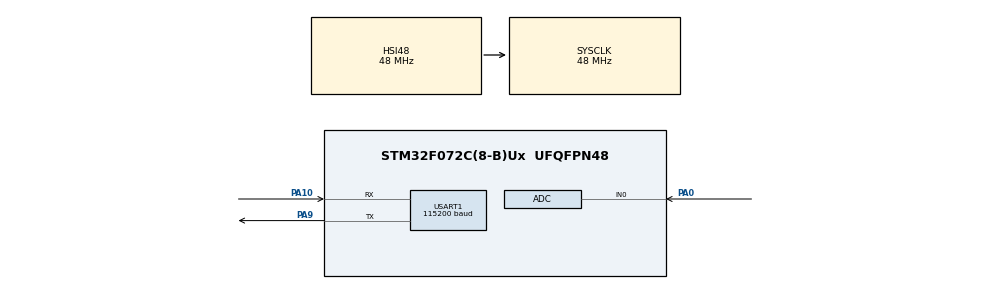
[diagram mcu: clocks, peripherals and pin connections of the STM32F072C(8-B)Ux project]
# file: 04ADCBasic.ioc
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Mcu.Family=STM32F0
Mcu.Name=STM32F072C(8-B)Ux
Mcu.Package=UFQFPN48
PA0.Mode=IN0
PA0.Signal=ADC_IN0
PA10.Mode=Asynchronous
PA10.Signal=USART1_RX
PA13.Mode=Serial_Wire
PA13.Signal=SYS_SWDIO
PA14.Mode=Serial_Wire
PA14.Signal=SYS_SWCLK
PA9.Mode=Asynchronous
PA9.Signal=USART1_TX
ProjectManager.HeapSize=0x200
ProjectManager.StackSize=0x400
ProjectManager.TargetToolchain=MDK-ARM V5.32
RCC.SYSCLKFreq_VALUE=48000000
RCC.SYSCLKSource=RCC_SYSCLKSOURCE_HSI48
USART1.BaudRate=115200
USART1.VirtualMode-Asynchronous=VM_ASYNC
board=custom

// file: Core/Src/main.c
/* USER CODE BEGIN Header */
/**
  ******************************************************************************
  * @file           : main.c
  * @brief          : Main program body
  ******************************************************************************
  * @attention
  *
  * Copyright (c) 2026 STMicroelectronics.
  * All rights reserved.
  *
  * This software is licensed under terms that can be found in the LICENSE file
  * in the root directory of this software component.
  * If no LICENSE file comes with this software, it is provided AS-IS.
  *
  ******************************************************************************
  */
/* USER CODE END Header */
#include "main.h"

/* USER CODE BEGIN Includes */
#include <stdio.h>
/*
 * ADC_IN0 单次采样：PA0 模拟输入，12 位结果范围 0..4095；
 * USART1 PA9 输出原始值和估算电压。PA0 必须保持在 0..VDDA，
 * 高阻信号源可能需要更长采样时间或外部缓冲器。
 */
/* USER CODE END Includes */

/* USER CODE BEGIN PD */
/* 假定模拟电源电压，单位 mV；修改它只改变显示换算值。 */
#define ADC_VDDA_MV 3300U
/* USER CODE END PD */

ADC_HandleTypeDef hadc;

UART_HandleTypeDef huart1;

void SystemClock_Config(void);
static void MX_GPIO_Init(void);
static void MX_ADC_Init(void);
static void MX_USART1_UART_Init(void);
/* USER CODE BEGIN PFP */
static void App_Init(void);
static void App_Loop(void);
/* USER CODE END PFP */

/* USER CODE BEGIN 0 */
/** @brief 通过 USART1 阻塞输出 printf 数据，最长等待 100 ms。 */
int _write(int file,char *ptr,int len){(void)file;if(ptr==NULL||len<=0)return 0;return HAL_UART_Transmit(&huart1,(uint8_t*)ptr,(uint16_t)len,100U)==HAL_OK?len:-1;}
#if defined(__CC_ARM) || defined(__ARMCC_VERSION)
int fputc(int ch, FILE *stream){uint8_t byte=(uint8_t)ch;(void)stream;return HAL_UART_Transmit(&huart1,&byte,1U,100U)==HAL_OK?ch:EOF;}
#endif
/* ADC 校准补偿内部偏移，应在第一次转换前完成；失败时进入统一错误处理。 */
static void App_Init(void){if(HAL_ADCEx_Calibration_Start(&hadc)!=HAL_OK)Error_Handler();}
/*
 * 非连续软件触发模式要求每次重新启动转换。轮询最多等待 20 ms。
 * Voltage_mV = ADC_Raw × ADC_VDDA_MV / 4095；先乘后除减少整数截断，
 * 4095×3300 不会超过 uint32_t。每次转换后停止 ADC，500 ms 后重采样。
 */
static void App_Loop(void){if(HAL_ADC_Start(&hadc)!=HAL_OK)printf("ADC start error\r\n");else if(HAL_ADC_PollForConversion(&hadc,20U)!=HAL_OK){printf("ADC timeout/error\r\n");(void)HAL_ADC_Stop(&hadc);}else{uint32_t raw=HAL_ADC_GetValue(&hadc);printf("ADC Raw: %lu, Voltage: %lu mV\r\n",(unsigned long)raw,(unsigned long)((raw*ADC_VDDA_MV)/4095U));if(HAL_ADC_Stop(&hadc)!=HAL_OK)printf("ADC stop error\r\n");}HAL_Delay(500U);}
/* USER CODE END 0 */

int main(void)
{

  /* MCU Configuration--------------------------------------------------------*/

  /* Reset of all peripherals, Initializes the Flash interface and the Systick. */
  HAL_Init();

  /* Configure the system clock */
  SystemClock_Config();

  /* Initialize all configured peripherals */
  MX_GPIO_Init();
  MX_ADC_Init();
  MX_USART1_UART_Init();
  /* USER CODE BEGIN 2 */
  App_Init();
  /* USER CODE END 2 */

  /* Infinite loop */
  /* USER CODE BEGIN WHILE */
  while (1)
  {
    App_Loop();
    /* USER CODE END WHILE */

  }
}

void SystemClock_Config(void)
{
  RCC_OscInitTypeDef RCC_OscInitStruct = {0};
  RCC_ClkInitTypeDef RCC_ClkInitStruct = {0};
  RCC_PeriphCLKInitTypeDef PeriphClkInit = {0};

  /** Initializes the RCC Oscillators according to the specified parameters
  * in the RCC_OscInitTypeDef structure.
  */
  RCC_OscInitStruct.OscillatorType = RCC_OSCILLATORTYPE_HSI14|RCC_OSCILLATORTYPE_HSI48;
  RCC_OscInitStruct.HSI48State = RCC_HSI48_ON;
  RCC_OscInitStruct.HSI14State = RCC_HSI14_ON;
  RCC_OscInitStruct.HSI14CalibrationValue = 16;
  RCC_OscInitStruct.PLL.PLLState = RCC_PLL_NONE;
  if (HAL_RCC_OscConfig(&RCC_OscInitStruct) != HAL_OK)
  {
    Error_Handler();
  }

  /** Initializes the CPU, AHB and APB buses clocks
  */
  RCC_ClkInitStruct.ClockType = RCC_CLOCKTYPE_HCLK|RCC_CLOCKTYPE_SYSCLK
                              |RCC_CLOCKTYPE_PCLK1;
  RCC_ClkInitStruct.SYSCLKSource = RCC_SYSCLKSOURCE_HSI48;
  RCC_ClkInitStruct.AHBCLKDivider = RCC_SYSCLK_DIV1;
  RCC_ClkInitStruct.APB1CLKDivider = RCC_HCLK_DIV1;

  if (HAL_RCC_ClockConfig(&RCC_ClkInitStruct, FLASH_LATENCY_1) != HAL_OK)
  {
    Error_Handler();
  }
  PeriphClkInit.PeriphClockSelection = RCC_PERIPHCLK_USART1;
  PeriphClkInit.Usart1ClockSelection = RCC_USART1CLKSOURCE_PCLK1;
  if (HAL_RCCEx_PeriphCLKConfig(&PeriphClkInit) != HAL_OK)
  {
    Error_Handler();
  }
}

static void MX_ADC_Init(void)
{

  ADC_ChannelConfTypeDef sConfig = {0};

  /** Configure the global features of the ADC (Clock, Resolution, Data Alignment and number of conversion)
  */
  hadc.Instance = ADC1;
  hadc.Init.ClockPrescaler = ADC_CLOCK_ASYNC_DIV1;
  hadc.Init.Resolution = ADC_RESOLUTION_12B;
  hadc.Init.DataAlign = ADC_DATAALIGN_RIGHT;
  hadc.Init.ScanConvMode = ADC_SCAN_DIRECTION_FORWARD;
  hadc.Init.EOCSelection = ADC_EOC_SINGLE_CONV;
  hadc.Init.LowPowerAutoWait = DISABLE;
  hadc.Init.LowPowerAutoPowerOff = DISABLE;
  hadc.Init.ContinuousConvMode = DISABLE;
  hadc.Init.DiscontinuousConvMode = DISABLE;
  hadc.Init.ExternalTrigConv = ADC_SOFTWARE_START;
  hadc.Init.ExternalTrigConvEdge = ADC_EXTERNALTRIGCONVEDGE_NONE;
  hadc.Init.DMAContinuousRequests = DISABLE;
  hadc.Init.Overrun = ADC_OVR_DATA_PRESERVED;
  if (HAL_ADC_Init(&hadc) != HAL_OK)
  {
    Error_Handler();
  }

  /** Configure for the selected ADC regular channel to be converted.
  */
  sConfig.Channel = ADC_CHANNEL_0;
  sConfig.Rank = ADC_RANK_CHANNEL_NUMBER;
  sConfig.SamplingTime = ADC_SAMPLETIME_1CYCLE_5;
  if (HAL_ADC_ConfigChannel(&hadc, &sConfig) != HAL_OK)
  {
    Error_Handler();
  }

}

static void MX_USART1_UART_Init(void)
{

  huart1.Instance = USART1;
  huart1.Init.BaudRate = 115200;
  huart1.Init.WordLength = UART_WORDLENGTH_8B;
  huart1.Init.StopBits = UART_STOPBITS_1;
  huart1.Init.Parity = UART_PARITY_NONE;
  huart1.Init.Mode = UART_MODE_TX_RX;
  huart1.Init.HwFlowCtl = UART_HWCONTROL_NONE;
  huart1.Init.OverSampling = UART_OVERSAMPLING_16;
  huart1.Init.OneBitSampling = UART_ONE_BIT_SAMPLE_DISABLE;
  huart1.AdvancedInit.AdvFeatureInit = UART_ADVFEATURE_NO_INIT;
  if (HAL_UART_Init(&huart1) != HAL_OK)
  {
    Error_Handler();
  }

}

static void MX_GPIO_Init(void)
{

  /* GPIO Ports Clock Enable */
  __HAL_RCC_GPIOA_CLK_ENABLE();

}

void Error_Handler(void)
{
  __disable_irq();
  while (1)
  {
  }
}
